# LPC55S16 register map
Vendor: nxp.com; File version: 1.0
CPU: CM33 r2p0, little endian, MPU, FPU, VTOR, 3 interrupt priority bits
Registers are 32-bit, read-write, reset 0x0 unless marked. A register's access mark holds for its fields unless they carry their own. Offsets are from the block's base; [hi:lo] are bit positions; {n}, {i} and the like mark numbered series; 'fields as' and 'values as' point back to an identical list.

## CASPER
Base 0x400A5000
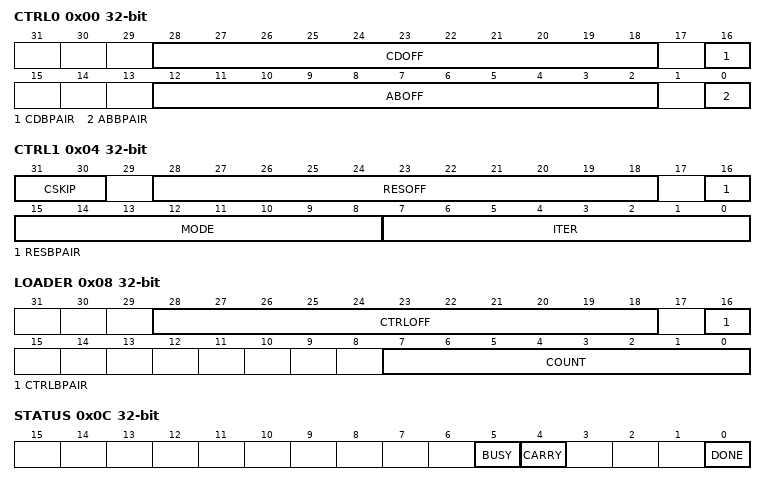
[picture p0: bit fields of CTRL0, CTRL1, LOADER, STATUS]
0x00 CTRL0 (reset mask 0x1FFD0005) — Contains the offsets of AB and CD in the RAM.
  [28:18] CDOFF — Word or DWord Offset of CD, with D at [2]=0 and C at [2]=1 as far as the code sees (normally will be an interleaved bank so only sequential to AHB). Word offset only allowed if 32 bit operation. Ideally not in the same RAM as the AB values
  [16] CDBPAIR — Which bank-pair the offset CDOFF is within. This must be 0 if only 2-up
    0=PAIR0 (Bank-pair 0 (1st)); 1=PAIR1 (Bank-pair 1 (2nd))
  [12:2] ABOFF — Word or DWord Offset of AB values, with B at [2]=0 and A at [2]=1 as far as the code sees (normally will be an interleaved bank so only sequential to AHB). Word offset only allowed if 32 bit operation. Ideally not in the same RAM as the CD values if 4-up
  [0] ABBPAIR — Which bank-pair the offset ABOFF is within. This must be 0 if only 2-up
    0=PAIR0 (Bank-pair 0 (1st)); 1=PAIR1 (Bank-pair 1 (2nd))
0x04 CTRL1 — Contains the opcode mode, iteration count, and result offset (in RAM) and also launches the accelerator. Note: with CP version: CTRL0 and CRTL1 can be written in one go with MCRR.
  [31:30] CSKIP — Skip rules on Carry if needed. This operation will be skipped based on Carry value (from previous operation) if not 0:
    0=NO_SKIP; 1=SKIP_IF_1 (Skip if Carry is 1); 2=SKIP_IF_0 (Skip if Carry is 0); 3=SET_AND_SKIP (Set CTRLOFF to CDOFF and Skip)
  [28:18] RESOFF — Word or DWord Offset of result. Word offset only allowed if 32 bit operation. Ideally not in the same RAM as the AB and CD values
  [16] RESBPAIR — Which bank-pair the offset RESOFF is within. This must be 0 if only 2-up. Ideally this is not the same bank as ABBPAIR (when 4-up supported)
    0=PAIR0 (Bank-pair 0 (1st)); 1=PAIR1 (Bank-pair 1 (2nd))
  [15:8] MODE — Operation mode to perform. write 0 means Accelerator is inactive. write others means accelerator is active.
  [7:0] ITER — Iteration counter. Is number_cycles - 1. write 0 means Does one cycle - does not iterate.
0x08 LOADER — Contains an optional loader to load into CTRL0/1 in steps to perform a set of operations.
  [28:18] CTRLOFF — DWord Offset of CTRL pair to load next.
  [16] CTRLBPAIR — Which bank-pair the offset CTRLOFF is within. This must be 0 if only 2-up. Does not matter which bank is used as this is loaded when not performing an operation.
    0=PAIR0 (Bank-pair 0 (1st)); 1=PAIR1 (Bank-pair 1 (2nd))
  [7:0] COUNT — Number of control pairs to load 0 relative (so 1 means load 1). write 1 means Does one op - does not iterate, write N means N control pairs to load
0x0C STATUS — Indicates operational status and would contain the carry bit if used.
  [5] BUSY ro — Indicates if the accelerator is busy performing an operation
    0=IDLE (Not busy - is idle); 1=BUSY (Is busy)
  [4] CARRY ro — Last carry value if operation produced a carry bit
    0=NO_CARRY (Carry was 0 or no carry); 1=CARRY (Carry was 1)
  [0] DONE — Indicates if the accelerator has finished an operation. Write 1 to clear, or write CTRL1 to clear.
    0=BUSY (Busy or just cleared); 1=COMPLETED (Completed last operation)
0x10 INTENSET — Sets interrupts
  [0] DONE — Set if the accelerator should interrupt when done.
    0=NO_INTERRUPT (Do not interrupt when done); 1=INTERRUPT (Interrupt when done)
0x14 INTENCLR write-1-clears — Clears interrupts
  [0] DONE write-1-clears — Written to clear an interrupt set with INTENSET.
    0=IGNORED (If written 0, ignored); 1=NO_INTERRUPT (If written 1, do not Interrupt when done)
0x18 INTSTAT — Interrupt status bits (mask of INTENSET and STATUS)
  [0] DONE ro — If set, interrupt is caused by accelerator being done.
    0=NOT_CAUSED (Not caused by accelerator being done); 1=CAUSED (Caused by accelerator being done)
0x20 AREG — A register
  [31:0] REG_VALUE — Register to be fed into Multiplier. Is not normally written or read by application, but is available when accelerator not busy.
0x24 BREG — B register
  fields as AREG
0x28 CREG — C register
  fields as AREG
0x2C DREG — D register
  fields as AREG
{0x30+4i} RES{i} (i=0..3) — Result register {i}
  [31:0] REG_VALUE — Register to hold working result (from multiplier, adder/xor, etc). Is not normally written or read by application, but is available when accelerator not busy.
0x60 MASK — Optional mask register
  [31:0] MASK — Mask to apply as side channel countermeasure. 0: No mask to be used. N: Mask to XOR onto values
0x64 REMASK — Optional re-mask register
  fields as MASK
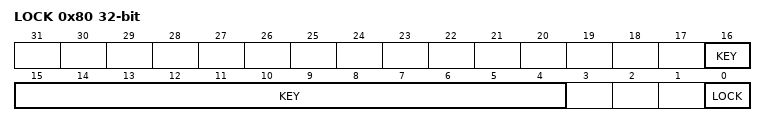
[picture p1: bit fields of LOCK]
0x80 LOCK — Security lock register
  [16:4] KEY — Must be written as 0x73D to change the register.
    0x73D=KWY_VALUE (If set during write, will allow lock or unlock)
  [0] LOCK — Reads back with security level locked to, or 0. Writes as 0 to unlock, 1 to lock.
    0=UNLOCK; 1=LOCK (Lock to current security level)
